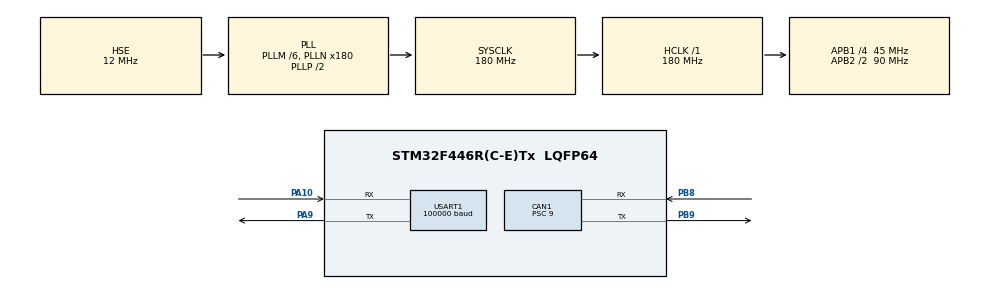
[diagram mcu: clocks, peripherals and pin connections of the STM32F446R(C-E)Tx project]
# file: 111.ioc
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CAN1.BS1=CAN_BS1_2TQ
CAN1.BS2=CAN_BS2_2TQ
CAN1.CalculateBaudRate=1000000
CAN1.CalculateTimeBit=1000
CAN1.CalculateTimeQuantum=200.0
CAN1.Prescaler=9
Mcu.Family=STM32F4
Mcu.Name=STM32F446R(C-E)Tx
Mcu.Package=LQFP64
NVIC.CAN1_RX0_IRQn=true\:0\:0\:false\:false\:true\:true\:true\:true
NVIC.CAN1_RX1_IRQn=true\:0\:0\:false\:false\:true\:true\:true\:true
NVIC.PriorityGroup=NVIC_PRIORITYGROUP_4
NVIC.TIM4_IRQn=true\:0\:0\:false\:false\:true\:true\:true\:true
NVIC.TIM5_IRQn=true\:0\:0\:false\:false\:true\:true\:true\:true
NVIC.USART1_IRQn=true\:0\:0\:false\:false\:true\:true\:true\:true
PA10.Mode=Asynchronous
PA10.Signal=USART1_RX
PA13.Mode=Serial_Wire
PA13.Signal=SYS_JTMS-SWDIO
PA14.Mode=Serial_Wire
PA14.Signal=SYS_JTCK-SWCLK
PA9.Mode=Asynchronous
PA9.Signal=USART1_TX
PB8.Mode=CAN_Activate
PB8.Signal=CAN1_RX
PB9.Mode=CAN_Activate
PB9.Signal=CAN1_TX
PH0-OSC_IN.Mode=HSE-External-Oscillator
PH0-OSC_IN.Signal=RCC_OSC_IN
PH1-OSC_OUT.Mode=HSE-External-Oscillator
PH1-OSC_OUT.Signal=RCC_OSC_OUT
ProjectManager.HeapSize=0x200
ProjectManager.StackSize=0x400
ProjectManager.TargetToolchain=CMake
RCC.AHBFreq_Value=180000000
RCC.APB1CLKDivider=RCC_HCLK_DIV4
RCC.APB1Freq_Value=45000000
RCC.APB1TimFreq_Value=90000000
RCC.APB2CLKDivider=RCC_HCLK_DIV2
RCC.APB2Freq_Value=90000000
RCC.APB2TimFreq_Value=180000000
RCC.CortexFreq_Value=180000000
RCC.HCLKFreq_Value=180000000
RCC.HSE_VALUE=12000000
RCC.PLLM=6
RCC.PLLN=180
RCC.PLLSourceVirtual=RCC_PLLSOURCE_HSE
RCC.SYSCLKFreq_VALUE=180000000
RCC.SYSCLKSource=RCC_SYSCLKSOURCE_PLLCLK
RCC.USBFreq_Value=180000000
RCC.VCOOutputFreq_Value=360000000
STMicroelectronics.X-CUBE-ALGOBUILD.1.4.0.LibraryCcDSPOoLibraryJjDSPOoLibrary=true
TIM4.Period=100-1
TIM4.Prescaler=84-1
TIM5.Period=1000-1
TIM5.Prescaler=84-1
USART1.BaudRate=100000
USART1.VirtualMode=VM_ASYNC
VP_STMicroelectronics.X-CUBE-ALGOBUILD_VS_DSPOoLibraryJjLibrary_1.4.0_1.4.0.Mode=DSPOoLibraryJjLibrary
VP_TIM4_VS_ClockSourceINT.Mode=Internal
VP_TIM5_VS_ClockSourceINT.Mode=Internal
board=custom

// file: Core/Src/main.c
/* USER CODE BEGIN Header */
/**
  ******************************************************************************
  * @file           : main.c
  * @brief          : Main program body
  ******************************************************************************
  * @attention
  *
  * Copyright (c) 2025 STMicroelectronics.
  * All rights reserved.
  *
  * This software is licensed under terms that can be found in the LICENSE file
  * in the root directory of this software component.
  * If no LICENSE file comes with this software, it is provided AS-IS.
  *
  ******************************************************************************
  */
/* USER CODE END Header */
#include "main.h"
#include "can.h"
#include "tim.h"
#include "usart.h"
#include "gpio.h"

/* USER CODE BEGIN Includes */
#include "task.h"
#include "drv_can.h"
/* USER CODE END Includes */

void SystemClock_Config(void);

int main(void)
{

  /* MCU Configuration--------------------------------------------------------*/

  /* Reset of all peripherals, Initializes the Flash interface and the Systick. */
  HAL_Init();

  /* Configure the system clock */
  SystemClock_Config();

  /* Initialize all configured peripherals */
  MX_GPIO_Init();
  MX_CAN1_Init();
  MX_TIM4_Init();
  MX_TIM5_Init();
  MX_USART1_UART_Init();
  /* USER CODE BEGIN 2 */
  Init_Task();

  /* USER CODE END 2 */

  /* Infinite loop */
  /* USER CODE BEGIN WHILE */
  while (1)
  {
    Start_Task();

    /* USER CODE END WHILE */

  }
}

void SystemClock_Config(void)
{
  RCC_OscInitTypeDef RCC_OscInitStruct = {0};
  RCC_ClkInitTypeDef RCC_ClkInitStruct = {0};

  /** Configure the main internal regulator output voltage
  */
  __HAL_RCC_PWR_CLK_ENABLE();
  __HAL_PWR_VOLTAGESCALING_CONFIG(PWR_REGULATOR_VOLTAGE_SCALE1);

  /** Initializes the RCC Oscillators according to the specified parameters
  * in the RCC_OscInitTypeDef structure.
  */
  RCC_OscInitStruct.OscillatorType = RCC_OSCILLATORTYPE_HSE;
  RCC_OscInitStruct.HSEState = RCC_HSE_ON;
  RCC_OscInitStruct.PLL.PLLState = RCC_PLL_ON;
  RCC_OscInitStruct.PLL.PLLSource = RCC_PLLSOURCE_HSE;
  RCC_OscInitStruct.PLL.PLLM = 6;
  RCC_OscInitStruct.PLL.PLLN = 180;
  RCC_OscInitStruct.PLL.PLLP = RCC_PLLP_DIV2;
  RCC_OscInitStruct.PLL.PLLQ = 2;
  RCC_OscInitStruct.PLL.PLLR = 2;
  if (HAL_RCC_OscConfig(&RCC_OscInitStruct) != HAL_OK)
  {
    Error_Handler();
  }

  /** Activate the Over-Drive mode
  */
  if (HAL_PWREx_EnableOverDrive() != HAL_OK)
  {
    Error_Handler();
  }

  /** Initializes the CPU, AHB and APB buses clocks
  */
  RCC_ClkInitStruct.ClockType = RCC_CLOCKTYPE_HCLK|RCC_CLOCKTYPE_SYSCLK
                              |RCC_CLOCKTYPE_PCLK1|RCC_CLOCKTYPE_PCLK2;
  RCC_ClkInitStruct.SYSCLKSource = RCC_SYSCLKSOURCE_PLLCLK;
  RCC_ClkInitStruct.AHBCLKDivider = RCC_SYSCLK_DIV1;
  RCC_ClkInitStruct.APB1CLKDivider = RCC_HCLK_DIV4;
  RCC_ClkInitStruct.APB2CLKDivider = RCC_HCLK_DIV2;

  if (HAL_RCC_ClockConfig(&RCC_ClkInitStruct, FLASH_LATENCY_5) != HAL_OK)
  {
    Error_Handler();
  }
}

void Error_Handler(void)
{
  __disable_irq();
  while (1)
  {
  }
}
